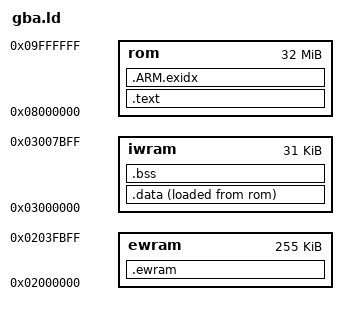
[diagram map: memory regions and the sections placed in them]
OUTPUT_ARCH(arm)
ENTRY(_start)
MEMORY { rom : ORIGIN = 0x08000000, LENGTH = 32M
         iwram : ORIGIN = 0x03000000, LENGTH = 31K
         ewram : ORIGIN = 0x02000000, LENGTH = 255K }
SECTIONS {
  .text : { KEEP(*(.crt0)) *(.text*) *(.glue_7) *(.glue_7t) *(.rodata*) . = ALIGN(4); } > rom
  .ARM.exidx : { *(.ARM.exidx*) } > rom
  . = ALIGN(4);
  .data : { __data_start = .; *(.iwram*) *(.data*) . = ALIGN(4); __data_end = .; } > iwram AT > rom
  __data_lma = LOADADDR(.data);
  .bss (NOLOAD) : { __bss_start = .; *(.bss*) *(COMMON) . = ALIGN(4); __bss_end = .; } > iwram
  .ewram (NOLOAD) : { *(.ewram*) } > ewram
  /DISCARD/ : { *(.comment) *(.ARM.attributes) }
}
